AUTOSAR XML (schema 00044)
package /ComponentTypes
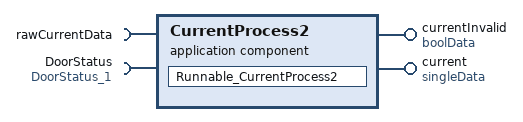
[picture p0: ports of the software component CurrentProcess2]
  application sw component type CurrentProcess2
    provide port currentInvalid: nonqueued-sender-com-spec=data, provided-interface=boolData
    provide port current: nonqueued-sender-com-spec=data, provided-interface=singleData
    require port rawCurrentData: nonqueued-receiver-com-spec{data-element=rawCurrentData, alive-timeout=0.3, init-value=32768}, required-interface=rawCurrentData
    require port DoorStatus: nonqueued-receiver-com-spec{data-element=DoorStatus, init-value=0}, required-interface=DoorStatus_1
    behavior CurrentProcess2_InternalBehavior
      data received event DRT_Runnable_CurrentProcess_rawCurrentData_rawCurrentData: start-on-event=Runnable_CurrentProcess2, data=rawCurrentData.rawCurrentData
      data receive error event DRET_Runnable_CurrentProcess_rawCurrentData_rawCurrentData: start-on-event=Runnable_CurrentProcess2, data=rawCurrentData.rawCurrentData
      runnable Runnable_CurrentProcess2
        data-receive-point-by-arguments:
          access REC_rawCurrentData_rawCurrentData: accessed-variable=rawCurrentData.rawCurrentData
          access REC_DoorStatus_DoorStatus: accessed-variable=DoorStatus.DoorStatus
        data-send-points:
          access SEND_current_data: accessed-variable=current.data
          access SEND_currentInvalid_data: accessed-variable=currentInvalid.data
  swc implementation CurrentProcess2_Implementation: behavior=CurrentProcess2_InternalBehavior
